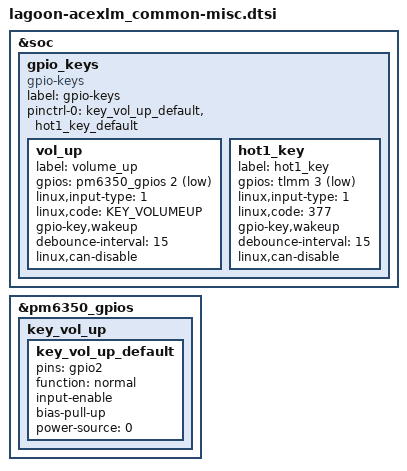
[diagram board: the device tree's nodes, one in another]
// SPDX-License-Identifier: GPL-2.0-only
/*
 * Copyright (c) 2018-2019, The Linux Foundation. All rights reserved.
 */
&soc {
        gpio_keys {
                compatible = "gpio-keys";
                label = "gpio-keys";

                pinctrl-names = "default";
                pinctrl-0 = <&key_vol_up_default &hot1_key_default>;

                vol_up {
                        label = "volume_up";
                        gpios = <&pm6350_gpios 2 GPIO_ACTIVE_LOW>;
                        linux,input-type = <1>;
                        linux,code = <KEY_VOLUMEUP>;
                        gpio-key,wakeup;
                        debounce-interval = <15>;
                        linux,can-disable;
                };

                hot1_key {
                       label = "hot1_key";
                       gpios = <&tlmm 3 1>;
                       linux,input-type = <1>;
                       linux,code = <377>;
                       gpio-key,wakeup;
                       debounce-interval = <15>;
                       linux,can-disable;
                };
        };
// 	Move to main dtb to prevent the dt parse error
//	pdc:interrupt-controller@b220000 {
//		qcom,pdc-ranges = <0 480 94>, <94 609 31>, <125 63 1>,
//                                 <126 655 12>, <138 139 15>;
//	};
};

&pm6350_gpios {
        key_vol_up {
                key_vol_up_default: key_vol_up_default {
                        pins = "gpio2";
                        function = "normal";
                        input-enable;
                        bias-pull-up;
                        power-source = <0>;
                };
        };
};

